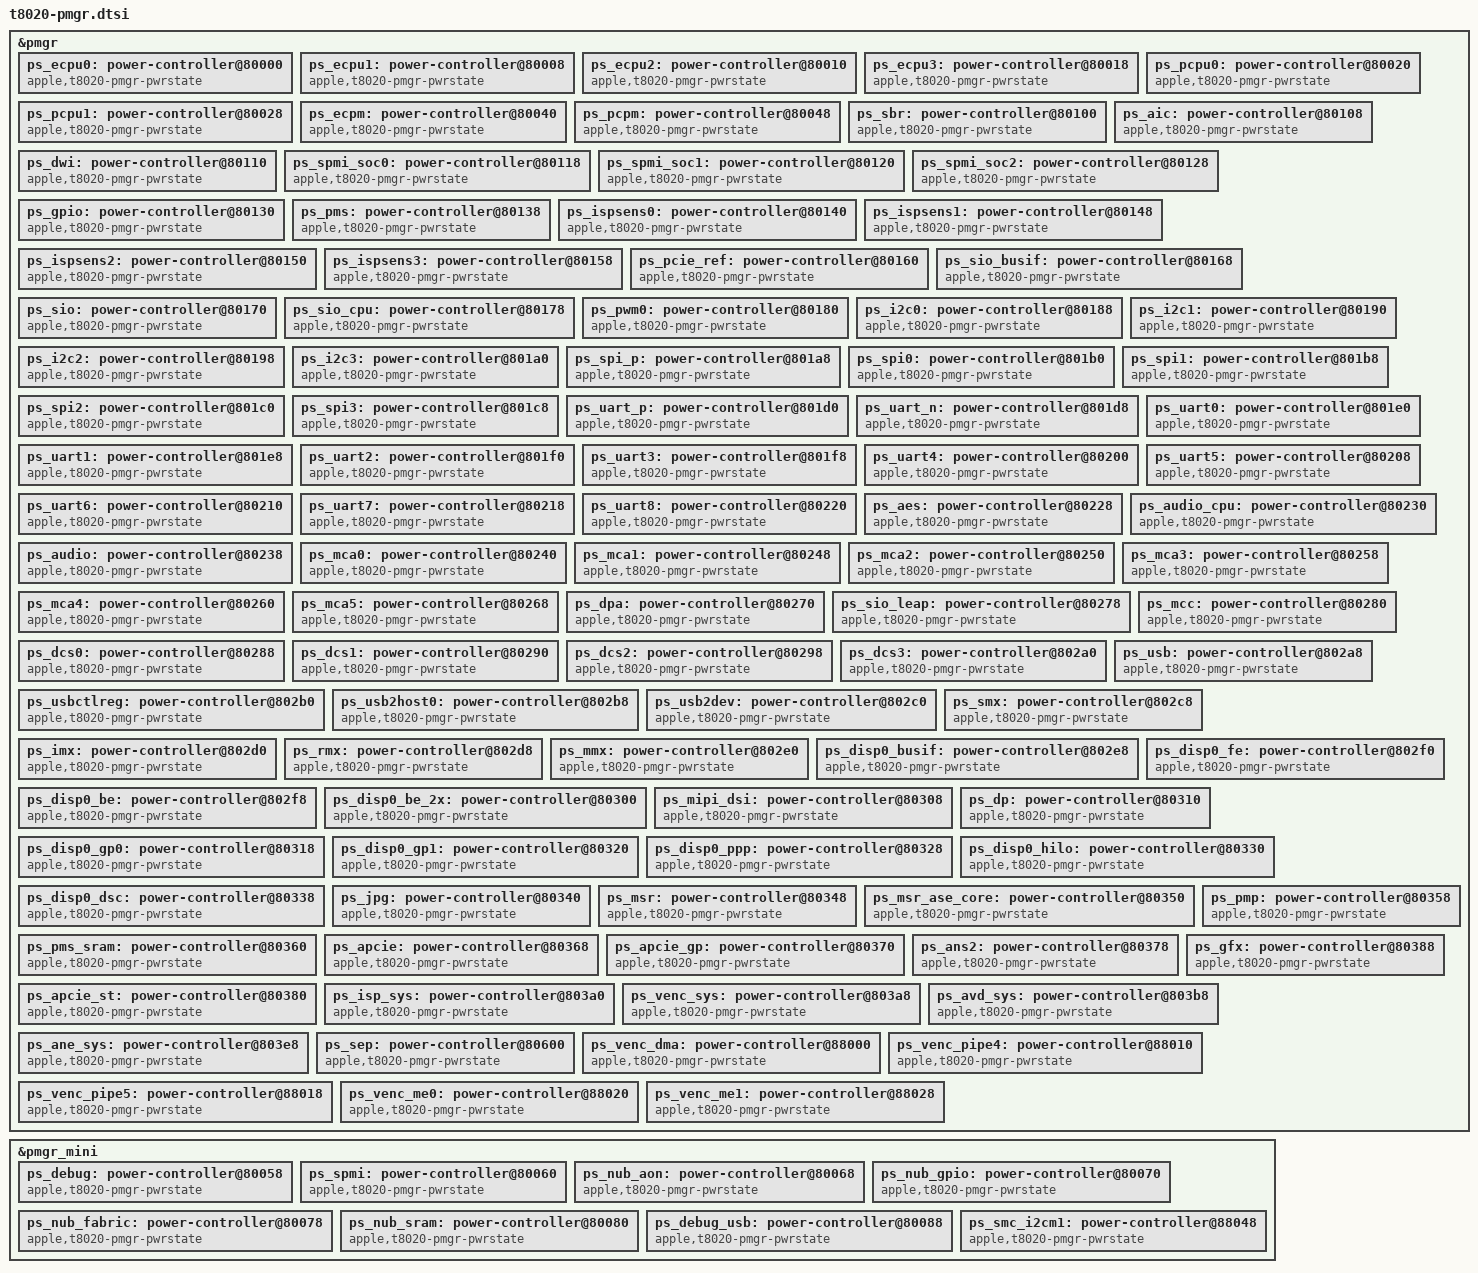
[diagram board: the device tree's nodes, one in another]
// SPDX-License-Identifier: GPL-2.0+ OR MIT
/*
 * PMGR power domains for the Apple T8020 "A12" SoC
 *
 * Generated by tools/gen-pmgr.sh from the ADT in the iPhone11,6 IPSW.
 * Do not edit by hand, regenerate instead.
 *
 * Copyright (c) 2026, kiki <kieran@lavato.net>
 */



&pmgr {

	ps_ecpu0: power-controller@80000 {
		compatible = "apple,t8020-pmgr-pwrstate", "apple,pmgr-pwrstate";
		reg = <0x80000 4>;
		#power-domain-cells = <0>;
		#reset-cells = <0>;
		label = "ecpu0";
	};

	ps_ecpu1: power-controller@80008 {
		compatible = "apple,t8020-pmgr-pwrstate", "apple,pmgr-pwrstate";
		reg = <0x80008 4>;
		#power-domain-cells = <0>;
		#reset-cells = <0>;
		label = "ecpu1";
	};

	ps_ecpu2: power-controller@80010 {
		compatible = "apple,t8020-pmgr-pwrstate", "apple,pmgr-pwrstate";
		reg = <0x80010 4>;
		#power-domain-cells = <0>;
		#reset-cells = <0>;
		label = "ecpu2";
	};

	ps_ecpu3: power-controller@80018 {
		compatible = "apple,t8020-pmgr-pwrstate", "apple,pmgr-pwrstate";
		reg = <0x80018 4>;
		#power-domain-cells = <0>;
		#reset-cells = <0>;
		label = "ecpu3";
	};

	ps_pcpu0: power-controller@80020 {
		compatible = "apple,t8020-pmgr-pwrstate", "apple,pmgr-pwrstate";
		reg = <0x80020 4>;
		#power-domain-cells = <0>;
		#reset-cells = <0>;
		label = "pcpu0";
	};

	ps_pcpu1: power-controller@80028 {
		compatible = "apple,t8020-pmgr-pwrstate", "apple,pmgr-pwrstate";
		reg = <0x80028 4>;
		#power-domain-cells = <0>;
		#reset-cells = <0>;
		label = "pcpu1";
	};

	ps_ecpm: power-controller@80040 {
		compatible = "apple,t8020-pmgr-pwrstate", "apple,pmgr-pwrstate";
		reg = <0x80040 4>;
		#power-domain-cells = <0>;
		#reset-cells = <0>;
		label = "ecpm";
	};

	ps_pcpm: power-controller@80048 {
		compatible = "apple,t8020-pmgr-pwrstate", "apple,pmgr-pwrstate";
		reg = <0x80048 4>;
		#power-domain-cells = <0>;
		#reset-cells = <0>;
		label = "pcpm";
	};

	ps_sbr: power-controller@80100 {
		compatible = "apple,t8020-pmgr-pwrstate", "apple,pmgr-pwrstate";
		reg = <0x80100 4>;
		#power-domain-cells = <0>;
		#reset-cells = <0>;
		label = "sbr";
		apple,always-on;
	};

	ps_aic: power-controller@80108 {
		compatible = "apple,t8020-pmgr-pwrstate", "apple,pmgr-pwrstate";
		reg = <0x80108 4>;
		#power-domain-cells = <0>;
		#reset-cells = <0>;
		label = "aic";
	};

	ps_dwi: power-controller@80110 {
		compatible = "apple,t8020-pmgr-pwrstate", "apple,pmgr-pwrstate";
		reg = <0x80110 4>;
		#power-domain-cells = <0>;
		#reset-cells = <0>;
		label = "dwi";
	};

	ps_spmi_soc0: power-controller@80118 {
		compatible = "apple,t8020-pmgr-pwrstate", "apple,pmgr-pwrstate";
		reg = <0x80118 4>;
		#power-domain-cells = <0>;
		#reset-cells = <0>;
		label = "spmi_soc0";
	};

	ps_spmi_soc1: power-controller@80120 {
		compatible = "apple,t8020-pmgr-pwrstate", "apple,pmgr-pwrstate";
		reg = <0x80120 4>;
		#power-domain-cells = <0>;
		#reset-cells = <0>;
		label = "spmi_soc1";
	};

	ps_spmi_soc2: power-controller@80128 {
		compatible = "apple,t8020-pmgr-pwrstate", "apple,pmgr-pwrstate";
		reg = <0x80128 4>;
		#power-domain-cells = <0>;
		#reset-cells = <0>;
		label = "spmi_soc2";
	};

	ps_gpio: power-controller@80130 {
		compatible = "apple,t8020-pmgr-pwrstate", "apple,pmgr-pwrstate";
		reg = <0x80130 4>;
		#power-domain-cells = <0>;
		#reset-cells = <0>;
		label = "gpio";
	};

	ps_pms: power-controller@80138 {
		compatible = "apple,t8020-pmgr-pwrstate", "apple,pmgr-pwrstate";
		reg = <0x80138 4>;
		#power-domain-cells = <0>;
		#reset-cells = <0>;
		label = "pms";
		apple,always-on;
	};

	ps_ispsens0: power-controller@80140 {
		compatible = "apple,t8020-pmgr-pwrstate", "apple,pmgr-pwrstate";
		reg = <0x80140 4>;
		#power-domain-cells = <0>;
		#reset-cells = <0>;
		label = "ispsens0";
	};

	ps_ispsens1: power-controller@80148 {
		compatible = "apple,t8020-pmgr-pwrstate", "apple,pmgr-pwrstate";
		reg = <0x80148 4>;
		#power-domain-cells = <0>;
		#reset-cells = <0>;
		label = "ispsens1";
	};

	ps_ispsens2: power-controller@80150 {
		compatible = "apple,t8020-pmgr-pwrstate", "apple,pmgr-pwrstate";
		reg = <0x80150 4>;
		#power-domain-cells = <0>;
		#reset-cells = <0>;
		label = "ispsens2";
	};

	ps_ispsens3: power-controller@80158 {
		compatible = "apple,t8020-pmgr-pwrstate", "apple,pmgr-pwrstate";
		reg = <0x80158 4>;
		#power-domain-cells = <0>;
		#reset-cells = <0>;
		label = "ispsens3";
	};

	ps_pcie_ref: power-controller@80160 {
		compatible = "apple,t8020-pmgr-pwrstate", "apple,pmgr-pwrstate";
		reg = <0x80160 4>;
		#power-domain-cells = <0>;
		#reset-cells = <0>;
		label = "pcie_ref";
	};

	ps_sio_busif: power-controller@80168 {
		compatible = "apple,t8020-pmgr-pwrstate", "apple,pmgr-pwrstate";
		reg = <0x80168 4>;
		#power-domain-cells = <0>;
		#reset-cells = <0>;
		label = "sio_busif";
	};

	ps_sio: power-controller@80170 {
		compatible = "apple,t8020-pmgr-pwrstate", "apple,pmgr-pwrstate";
		reg = <0x80170 4>;
		#power-domain-cells = <0>;
		#reset-cells = <0>;
		label = "sio";
		power-domains = <&ps_sio_busif>;
	};

	ps_sio_cpu: power-controller@80178 {
		compatible = "apple,t8020-pmgr-pwrstate", "apple,pmgr-pwrstate";
		reg = <0x80178 4>;
		#power-domain-cells = <0>;
		#reset-cells = <0>;
		label = "sio_cpu";
		power-domains = <&ps_sio>;
	};

	ps_pwm0: power-controller@80180 {
		compatible = "apple,t8020-pmgr-pwrstate", "apple,pmgr-pwrstate";
		reg = <0x80180 4>;
		#power-domain-cells = <0>;
		#reset-cells = <0>;
		label = "pwm0";
		power-domains = <&ps_sio>;
	};

	ps_i2c0: power-controller@80188 {
		compatible = "apple,t8020-pmgr-pwrstate", "apple,pmgr-pwrstate";
		reg = <0x80188 4>;
		#power-domain-cells = <0>;
		#reset-cells = <0>;
		label = "i2c0";
		power-domains = <&ps_sio>;
	};

	ps_i2c1: power-controller@80190 {
		compatible = "apple,t8020-pmgr-pwrstate", "apple,pmgr-pwrstate";
		reg = <0x80190 4>;
		#power-domain-cells = <0>;
		#reset-cells = <0>;
		label = "i2c1";
		power-domains = <&ps_sio>;
	};

	ps_i2c2: power-controller@80198 {
		compatible = "apple,t8020-pmgr-pwrstate", "apple,pmgr-pwrstate";
		reg = <0x80198 4>;
		#power-domain-cells = <0>;
		#reset-cells = <0>;
		label = "i2c2";
		power-domains = <&ps_sio>;
	};

	ps_i2c3: power-controller@801a0 {
		compatible = "apple,t8020-pmgr-pwrstate", "apple,pmgr-pwrstate";
		reg = <0x801a0 4>;
		#power-domain-cells = <0>;
		#reset-cells = <0>;
		label = "i2c3";
		power-domains = <&ps_sio>;
	};

	ps_spi_p: power-controller@801a8 {
		compatible = "apple,t8020-pmgr-pwrstate", "apple,pmgr-pwrstate";
		reg = <0x801a8 4>;
		#power-domain-cells = <0>;
		#reset-cells = <0>;
		label = "spi_p";
		power-domains = <&ps_sio_busif>, <&ps_sio>;
	};

	ps_spi0: power-controller@801b0 {
		compatible = "apple,t8020-pmgr-pwrstate", "apple,pmgr-pwrstate";
		reg = <0x801b0 4>;
		#power-domain-cells = <0>;
		#reset-cells = <0>;
		label = "spi0";
		power-domains = <&ps_spi_p>;
	};

	ps_spi1: power-controller@801b8 {
		compatible = "apple,t8020-pmgr-pwrstate", "apple,pmgr-pwrstate";
		reg = <0x801b8 4>;
		#power-domain-cells = <0>;
		#reset-cells = <0>;
		label = "spi1";
		power-domains = <&ps_spi_p>;
	};

	ps_spi2: power-controller@801c0 {
		compatible = "apple,t8020-pmgr-pwrstate", "apple,pmgr-pwrstate";
		reg = <0x801c0 4>;
		#power-domain-cells = <0>;
		#reset-cells = <0>;
		label = "spi2";
		power-domains = <&ps_spi_p>;
	};

	ps_spi3: power-controller@801c8 {
		compatible = "apple,t8020-pmgr-pwrstate", "apple,pmgr-pwrstate";
		reg = <0x801c8 4>;
		#power-domain-cells = <0>;
		#reset-cells = <0>;
		label = "spi3";
		power-domains = <&ps_spi_p>;
	};

	ps_uart_p: power-controller@801d0 {
		compatible = "apple,t8020-pmgr-pwrstate", "apple,pmgr-pwrstate";
		reg = <0x801d0 4>;
		#power-domain-cells = <0>;
		#reset-cells = <0>;
		label = "uart_p";
		power-domains = <&ps_sio>;
	};

	ps_uart_n: power-controller@801d8 {
		compatible = "apple,t8020-pmgr-pwrstate", "apple,pmgr-pwrstate";
		reg = <0x801d8 4>;
		#power-domain-cells = <0>;
		#reset-cells = <0>;
		label = "uart_n";
		power-domains = <&ps_uart_p>;
	};

	ps_uart0: power-controller@801e0 {
		compatible = "apple,t8020-pmgr-pwrstate", "apple,pmgr-pwrstate";
		reg = <0x801e0 4>;
		#power-domain-cells = <0>;
		#reset-cells = <0>;
		label = "uart0";
		power-domains = <&ps_uart_p>;
	};

	ps_uart1: power-controller@801e8 {
		compatible = "apple,t8020-pmgr-pwrstate", "apple,pmgr-pwrstate";
		reg = <0x801e8 4>;
		#power-domain-cells = <0>;
		#reset-cells = <0>;
		label = "uart1";
		power-domains = <&ps_uart_p>;
	};

	ps_uart2: power-controller@801f0 {
		compatible = "apple,t8020-pmgr-pwrstate", "apple,pmgr-pwrstate";
		reg = <0x801f0 4>;
		#power-domain-cells = <0>;
		#reset-cells = <0>;
		label = "uart2";
		power-domains = <&ps_uart_p>;
	};

	ps_uart3: power-controller@801f8 {
		compatible = "apple,t8020-pmgr-pwrstate", "apple,pmgr-pwrstate";
		reg = <0x801f8 4>;
		#power-domain-cells = <0>;
		#reset-cells = <0>;
		label = "uart3";
		power-domains = <&ps_uart_p>;
	};

	ps_uart4: power-controller@80200 {
		compatible = "apple,t8020-pmgr-pwrstate", "apple,pmgr-pwrstate";
		reg = <0x80200 4>;
		#power-domain-cells = <0>;
		#reset-cells = <0>;
		label = "uart4";
		power-domains = <&ps_uart_p>;
	};

	ps_uart5: power-controller@80208 {
		compatible = "apple,t8020-pmgr-pwrstate", "apple,pmgr-pwrstate";
		reg = <0x80208 4>;
		#power-domain-cells = <0>;
		#reset-cells = <0>;
		label = "uart5";
		power-domains = <&ps_uart_p>;
	};

	ps_uart6: power-controller@80210 {
		compatible = "apple,t8020-pmgr-pwrstate", "apple,pmgr-pwrstate";
		reg = <0x80210 4>;
		#power-domain-cells = <0>;
		#reset-cells = <0>;
		label = "uart6";
		power-domains = <&ps_uart_p>;
	};

	ps_uart7: power-controller@80218 {
		compatible = "apple,t8020-pmgr-pwrstate", "apple,pmgr-pwrstate";
		reg = <0x80218 4>;
		#power-domain-cells = <0>;
		#reset-cells = <0>;
		label = "uart7";
		power-domains = <&ps_uart_p>;
	};

	ps_uart8: power-controller@80220 {
		compatible = "apple,t8020-pmgr-pwrstate", "apple,pmgr-pwrstate";
		reg = <0x80220 4>;
		#power-domain-cells = <0>;
		#reset-cells = <0>;
		label = "uart8";
		power-domains = <&ps_uart_p>;
	};

	ps_aes: power-controller@80228 {
		compatible = "apple,t8020-pmgr-pwrstate", "apple,pmgr-pwrstate";
		reg = <0x80228 4>;
		#power-domain-cells = <0>;
		#reset-cells = <0>;
		label = "aes";
		power-domains = <&ps_sio>;
	};

	ps_audio_cpu: power-controller@80230 {
		compatible = "apple,t8020-pmgr-pwrstate", "apple,pmgr-pwrstate";
		reg = <0x80230 4>;
		#power-domain-cells = <0>;
		#reset-cells = <0>;
		label = "audio_cpu";
		power-domains = <&ps_sio>;
	};

	ps_audio: power-controller@80238 {
		compatible = "apple,t8020-pmgr-pwrstate", "apple,pmgr-pwrstate";
		reg = <0x80238 4>;
		#power-domain-cells = <0>;
		#reset-cells = <0>;
		label = "audio";
		power-domains = <&ps_sio>;
	};

	ps_mca0: power-controller@80240 {
		compatible = "apple,t8020-pmgr-pwrstate", "apple,pmgr-pwrstate";
		reg = <0x80240 4>;
		#power-domain-cells = <0>;
		#reset-cells = <0>;
		label = "mca0";
		power-domains = <&ps_audio>;
	};

	ps_mca1: power-controller@80248 {
		compatible = "apple,t8020-pmgr-pwrstate", "apple,pmgr-pwrstate";
		reg = <0x80248 4>;
		#power-domain-cells = <0>;
		#reset-cells = <0>;
		label = "mca1";
		power-domains = <&ps_audio>;
	};

	ps_mca2: power-controller@80250 {
		compatible = "apple,t8020-pmgr-pwrstate", "apple,pmgr-pwrstate";
		reg = <0x80250 4>;
		#power-domain-cells = <0>;
		#reset-cells = <0>;
		label = "mca2";
		power-domains = <&ps_audio>;
	};

	ps_mca3: power-controller@80258 {
		compatible = "apple,t8020-pmgr-pwrstate", "apple,pmgr-pwrstate";
		reg = <0x80258 4>;
		#power-domain-cells = <0>;
		#reset-cells = <0>;
		label = "mca3";
		power-domains = <&ps_audio>;
	};

	ps_mca4: power-controller@80260 {
		compatible = "apple,t8020-pmgr-pwrstate", "apple,pmgr-pwrstate";
		reg = <0x80260 4>;
		#power-domain-cells = <0>;
		#reset-cells = <0>;
		label = "mca4";
		power-domains = <&ps_audio>;
	};

	ps_mca5: power-controller@80268 {
		compatible = "apple,t8020-pmgr-pwrstate", "apple,pmgr-pwrstate";
		reg = <0x80268 4>;
		#power-domain-cells = <0>;
		#reset-cells = <0>;
		label = "mca5";
		power-domains = <&ps_audio>;
	};

	ps_dpa: power-controller@80270 {
		compatible = "apple,t8020-pmgr-pwrstate", "apple,pmgr-pwrstate";
		reg = <0x80270 4>;
		#power-domain-cells = <0>;
		#reset-cells = <0>;
		label = "dpa";
		power-domains = <&ps_audio>;
	};

	ps_sio_leap: power-controller@80278 {
		compatible = "apple,t8020-pmgr-pwrstate", "apple,pmgr-pwrstate";
		reg = <0x80278 4>;
		#power-domain-cells = <0>;
		#reset-cells = <0>;
		label = "sio_leap";
		power-domains = <&ps_audio>;
	};

	ps_mcc: power-controller@80280 {
		compatible = "apple,t8020-pmgr-pwrstate", "apple,pmgr-pwrstate";
		reg = <0x80280 4>;
		#power-domain-cells = <0>;
		#reset-cells = <0>;
		label = "mcc";
		apple,always-on;
	};

	ps_dcs0: power-controller@80288 {
		compatible = "apple,t8020-pmgr-pwrstate", "apple,pmgr-pwrstate";
		reg = <0x80288 4>;
		#power-domain-cells = <0>;
		#reset-cells = <0>;
		label = "dcs0";
		apple,always-on;
	};

	ps_dcs1: power-controller@80290 {
		compatible = "apple,t8020-pmgr-pwrstate", "apple,pmgr-pwrstate";
		reg = <0x80290 4>;
		#power-domain-cells = <0>;
		#reset-cells = <0>;
		label = "dcs1";
		apple,always-on;
	};

	ps_dcs2: power-controller@80298 {
		compatible = "apple,t8020-pmgr-pwrstate", "apple,pmgr-pwrstate";
		reg = <0x80298 4>;
		#power-domain-cells = <0>;
		#reset-cells = <0>;
		label = "dcs2";
		apple,always-on;
	};

	ps_dcs3: power-controller@802a0 {
		compatible = "apple,t8020-pmgr-pwrstate", "apple,pmgr-pwrstate";
		reg = <0x802a0 4>;
		#power-domain-cells = <0>;
		#reset-cells = <0>;
		label = "dcs3";
		apple,always-on;
	};

	ps_usb: power-controller@802a8 {
		compatible = "apple,t8020-pmgr-pwrstate", "apple,pmgr-pwrstate";
		reg = <0x802a8 4>;
		#power-domain-cells = <0>;
		#reset-cells = <0>;
		label = "usb";
	};

	ps_usbctlreg: power-controller@802b0 {
		compatible = "apple,t8020-pmgr-pwrstate", "apple,pmgr-pwrstate";
		reg = <0x802b0 4>;
		#power-domain-cells = <0>;
		#reset-cells = <0>;
		label = "usbctlreg";
		power-domains = <&ps_usb>;
	};

	ps_usb2host0: power-controller@802b8 {
		compatible = "apple,t8020-pmgr-pwrstate", "apple,pmgr-pwrstate";
		reg = <0x802b8 4>;
		#power-domain-cells = <0>;
		#reset-cells = <0>;
		label = "usb2host0";
		power-domains = <&ps_usbctlreg>;
	};

	ps_usb2dev: power-controller@802c0 {
		compatible = "apple,t8020-pmgr-pwrstate", "apple,pmgr-pwrstate";
		reg = <0x802c0 4>;
		#power-domain-cells = <0>;
		#reset-cells = <0>;
		label = "usb2dev";
		power-domains = <&ps_usb>;
	};

	ps_smx: power-controller@802c8 {
		compatible = "apple,t8020-pmgr-pwrstate", "apple,pmgr-pwrstate";
		reg = <0x802c8 4>;
		#power-domain-cells = <0>;
		#reset-cells = <0>;
		label = "smx";
		apple,always-on;
	};

	ps_imx: power-controller@802d0 {
		compatible = "apple,t8020-pmgr-pwrstate", "apple,pmgr-pwrstate";
		reg = <0x802d0 4>;
		#power-domain-cells = <0>;
		#reset-cells = <0>;
		label = "imx";
		apple,always-on;
	};

	ps_rmx: power-controller@802d8 {
		compatible = "apple,t8020-pmgr-pwrstate", "apple,pmgr-pwrstate";
		reg = <0x802d8 4>;
		#power-domain-cells = <0>;
		#reset-cells = <0>;
		label = "rmx";
	};

	ps_mmx: power-controller@802e0 {
		compatible = "apple,t8020-pmgr-pwrstate", "apple,pmgr-pwrstate";
		reg = <0x802e0 4>;
		#power-domain-cells = <0>;
		#reset-cells = <0>;
		label = "mmx";
	};

	ps_disp0_busif: power-controller@802e8 {
		compatible = "apple,t8020-pmgr-pwrstate", "apple,pmgr-pwrstate";
		reg = <0x802e8 4>;
		#power-domain-cells = <0>;
		#reset-cells = <0>;
		label = "disp0_busif";
		power-domains = <&ps_rmx>;
	};

	ps_disp0_fe: power-controller@802f0 {
		compatible = "apple,t8020-pmgr-pwrstate", "apple,pmgr-pwrstate";
		reg = <0x802f0 4>;
		#power-domain-cells = <0>;
		#reset-cells = <0>;
		label = "disp0_fe";
		power-domains = <&ps_disp0_busif>;
	};

	ps_disp0_be: power-controller@802f8 {
		compatible = "apple,t8020-pmgr-pwrstate", "apple,pmgr-pwrstate";
		reg = <0x802f8 4>;
		#power-domain-cells = <0>;
		#reset-cells = <0>;
		label = "disp0_be";
		power-domains = <&ps_disp0_fe>;
	};

	ps_disp0_be_2x: power-controller@80300 {
		compatible = "apple,t8020-pmgr-pwrstate", "apple,pmgr-pwrstate";
		reg = <0x80300 4>;
		#power-domain-cells = <0>;
		#reset-cells = <0>;
		label = "disp0_be_2x";
	};

	ps_mipi_dsi: power-controller@80308 {
		compatible = "apple,t8020-pmgr-pwrstate", "apple,pmgr-pwrstate";
		reg = <0x80308 4>;
		#power-domain-cells = <0>;
		#reset-cells = <0>;
		label = "mipi_dsi";
		power-domains = <&ps_disp0_be>;
	};

	ps_dp: power-controller@80310 {
		compatible = "apple,t8020-pmgr-pwrstate", "apple,pmgr-pwrstate";
		reg = <0x80310 4>;
		#power-domain-cells = <0>;
		#reset-cells = <0>;
		label = "dp";
		power-domains = <&ps_disp0_be>;
	};

	ps_disp0_gp0: power-controller@80318 {
		compatible = "apple,t8020-pmgr-pwrstate", "apple,pmgr-pwrstate";
		reg = <0x80318 4>;
		#power-domain-cells = <0>;
		#reset-cells = <0>;
		label = "disp0_gp0";
		power-domains = <&ps_disp0_be>;
	};

	ps_disp0_gp1: power-controller@80320 {
		compatible = "apple,t8020-pmgr-pwrstate", "apple,pmgr-pwrstate";
		reg = <0x80320 4>;
		#power-domain-cells = <0>;
		#reset-cells = <0>;
		label = "disp0_gp1";
		power-domains = <&ps_disp0_gp0>;
	};

	ps_disp0_ppp: power-controller@80328 {
		compatible = "apple,t8020-pmgr-pwrstate", "apple,pmgr-pwrstate";
		reg = <0x80328 4>;
		#power-domain-cells = <0>;
		#reset-cells = <0>;
		label = "disp0_ppp";
		power-domains = <&ps_disp0_gp1>;
	};

	ps_disp0_hilo: power-controller@80330 {
		compatible = "apple,t8020-pmgr-pwrstate", "apple,pmgr-pwrstate";
		reg = <0x80330 4>;
		#power-domain-cells = <0>;
		#reset-cells = <0>;
		label = "disp0_hilo";
		power-domains = <&ps_disp0_ppp>;
	};

	ps_disp0_dsc: power-controller@80338 {
		compatible = "apple,t8020-pmgr-pwrstate", "apple,pmgr-pwrstate";
		reg = <0x80338 4>;
		#power-domain-cells = <0>;
		#reset-cells = <0>;
		label = "disp0_dsc";
		power-domains = <&ps_disp0_be>;
	};

	ps_jpg: power-controller@80340 {
		compatible = "apple,t8020-pmgr-pwrstate", "apple,pmgr-pwrstate";
		reg = <0x80340 4>;
		#power-domain-cells = <0>;
		#reset-cells = <0>;
		label = "jpg";
		power-domains = <&ps_mmx>;
	};

	ps_msr: power-controller@80348 {
		compatible = "apple,t8020-pmgr-pwrstate", "apple,pmgr-pwrstate";
		reg = <0x80348 4>;
		#power-domain-cells = <0>;
		#reset-cells = <0>;
		label = "msr";
		power-domains = <&ps_mmx>;
	};

	ps_msr_ase_core: power-controller@80350 {
		compatible = "apple,t8020-pmgr-pwrstate", "apple,pmgr-pwrstate";
		reg = <0x80350 4>;
		#power-domain-cells = <0>;
		#reset-cells = <0>;
		label = "msr_ase_core";
		power-domains = <&ps_msr>;
	};

	ps_pmp: power-controller@80358 {
		compatible = "apple,t8020-pmgr-pwrstate", "apple,pmgr-pwrstate";
		reg = <0x80358 4>;
		#power-domain-cells = <0>;
		#reset-cells = <0>;
		label = "pmp";
		apple,always-on;
	};

	ps_pms_sram: power-controller@80360 {
		compatible = "apple,t8020-pmgr-pwrstate", "apple,pmgr-pwrstate";
		reg = <0x80360 4>;
		#power-domain-cells = <0>;
		#reset-cells = <0>;
		label = "pms_sram";
		apple,always-on;
	};

	ps_apcie: power-controller@80368 {
		compatible = "apple,t8020-pmgr-pwrstate", "apple,pmgr-pwrstate";
		reg = <0x80368 4>;
		#power-domain-cells = <0>;
		#reset-cells = <0>;
		label = "apcie";
		power-domains = <&ps_imx>;
	};

	ps_apcie_gp: power-controller@80370 {
		compatible = "apple,t8020-pmgr-pwrstate", "apple,pmgr-pwrstate";
		reg = <0x80370 4>;
		#power-domain-cells = <0>;
		#reset-cells = <0>;
		label = "apcie_gp";
		power-domains = <&ps_apcie>;
	};

	ps_ans2: power-controller@80378 {
		compatible = "apple,t8020-pmgr-pwrstate", "apple,pmgr-pwrstate";
		reg = <0x80378 4>;
		#power-domain-cells = <0>;
		#reset-cells = <0>;
		label = "ans2";
	};

	ps_apcie_st: power-controller@80380 {
		compatible = "apple,t8020-pmgr-pwrstate", "apple,pmgr-pwrstate";
		reg = <0x80380 4>;
		#power-domain-cells = <0>;
		#reset-cells = <0>;
		label = "apcie_st";
		power-domains = <&ps_apcie>, <&ps_ans2>;
	};

	ps_gfx: power-controller@80388 {
		compatible = "apple,t8020-pmgr-pwrstate", "apple,pmgr-pwrstate";
		reg = <0x80388 4>;
		#power-domain-cells = <0>;
		#reset-cells = <0>;
		label = "gfx";
	};

	ps_isp_sys: power-controller@803a0 {
		compatible = "apple,t8020-pmgr-pwrstate", "apple,pmgr-pwrstate";
		reg = <0x803a0 4>;
		#power-domain-cells = <0>;
		#reset-cells = <0>;
		label = "isp_sys";
		power-domains = <&ps_rmx>;
	};

	ps_venc_sys: power-controller@803a8 {
		compatible = "apple,t8020-pmgr-pwrstate", "apple,pmgr-pwrstate";
		reg = <0x803a8 4>;
		#power-domain-cells = <0>;
		#reset-cells = <0>;
		label = "venc_sys";
		power-domains = <&ps_mmx>;
	};

	ps_avd_sys: power-controller@803b8 {
		compatible = "apple,t8020-pmgr-pwrstate", "apple,pmgr-pwrstate";
		reg = <0x803b8 4>;
		#power-domain-cells = <0>;
		#reset-cells = <0>;
		label = "avd_sys";
		power-domains = <&ps_mmx>;
	};

	ps_ane_sys: power-controller@803e8 {
		compatible = "apple,t8020-pmgr-pwrstate", "apple,pmgr-pwrstate";
		reg = <0x803e8 4>;
		#power-domain-cells = <0>;
		#reset-cells = <0>;
		label = "ane_sys";
		power-domains = <&ps_mmx>;
	};

	ps_sep: power-controller@80600 {
		compatible = "apple,t8020-pmgr-pwrstate", "apple,pmgr-pwrstate";
		reg = <0x80600 4>;
		#power-domain-cells = <0>;
		#reset-cells = <0>;
		label = "sep";
		apple,always-on;
	};

	ps_venc_dma: power-controller@88000 {
		compatible = "apple,t8020-pmgr-pwrstate", "apple,pmgr-pwrstate";
		reg = <0x88000 4>;
		#power-domain-cells = <0>;
		#reset-cells = <0>;
		label = "venc_dma";
		power-domains = <&ps_venc_sys>;
	};

	ps_venc_pipe4: power-controller@88010 {
		compatible = "apple,t8020-pmgr-pwrstate", "apple,pmgr-pwrstate";
		reg = <0x88010 4>;
		#power-domain-cells = <0>;
		#reset-cells = <0>;
		label = "venc_pipe4";
		power-domains = <&ps_venc_dma>;
	};

	ps_venc_pipe5: power-controller@88018 {
		compatible = "apple,t8020-pmgr-pwrstate", "apple,pmgr-pwrstate";
		reg = <0x88018 4>;
		#power-domain-cells = <0>;
		#reset-cells = <0>;
		label = "venc_pipe5";
		power-domains = <&ps_venc_dma>;
	};

	ps_venc_me0: power-controller@88020 {
		compatible = "apple,t8020-pmgr-pwrstate", "apple,pmgr-pwrstate";
		reg = <0x88020 4>;
		#power-domain-cells = <0>;
		#reset-cells = <0>;
		label = "venc_me0";
	};

	ps_venc_me1: power-controller@88028 {
		compatible = "apple,t8020-pmgr-pwrstate", "apple,pmgr-pwrstate";
		reg = <0x88028 4>;
		#power-domain-cells = <0>;
		#reset-cells = <0>;
		label = "venc_me1";
	};
};

&pmgr_mini {

	ps_debug: power-controller@80058 {
		compatible = "apple,t8020-pmgr-pwrstate", "apple,pmgr-pwrstate";
		reg = <0x80058 4>;
		#power-domain-cells = <0>;
		#reset-cells = <0>;
		label = "debug";
		apple,always-on;
	};

	ps_spmi: power-controller@80060 {
		compatible = "apple,t8020-pmgr-pwrstate", "apple,pmgr-pwrstate";
		reg = <0x80060 4>;
		#power-domain-cells = <0>;
		#reset-cells = <0>;
		label = "spmi";
		apple,always-on;
	};

	ps_nub_aon: power-controller@80068 {
		compatible = "apple,t8020-pmgr-pwrstate", "apple,pmgr-pwrstate";
		reg = <0x80068 4>;
		#power-domain-cells = <0>;
		#reset-cells = <0>;
		label = "nub_aon";
		apple,always-on;
	};

	ps_nub_gpio: power-controller@80070 {
		compatible = "apple,t8020-pmgr-pwrstate", "apple,pmgr-pwrstate";
		reg = <0x80070 4>;
		#power-domain-cells = <0>;
		#reset-cells = <0>;
		label = "nub_gpio";
		apple,always-on;
	};

	ps_nub_fabric: power-controller@80078 {
		compatible = "apple,t8020-pmgr-pwrstate", "apple,pmgr-pwrstate";
		reg = <0x80078 4>;
		#power-domain-cells = <0>;
		#reset-cells = <0>;
		label = "nub_fabric";
		apple,always-on;
	};

	ps_nub_sram: power-controller@80080 {
		compatible = "apple,t8020-pmgr-pwrstate", "apple,pmgr-pwrstate";
		reg = <0x80080 4>;
		#power-domain-cells = <0>;
		#reset-cells = <0>;
		label = "nub_sram";
		apple,always-on;
	};

	ps_debug_usb: power-controller@80088 {
		compatible = "apple,t8020-pmgr-pwrstate", "apple,pmgr-pwrstate";
		reg = <0x80088 4>;
		#power-domain-cells = <0>;
		#reset-cells = <0>;
		label = "debug_usb";
		apple,always-on;
		power-domains = <&ps_debug>;
	};

	ps_smc_i2cm1: power-controller@88048 {
		compatible = "apple,t8020-pmgr-pwrstate", "apple,pmgr-pwrstate";
		reg = <0x88048 4>;
		#power-domain-cells = <0>;
		#reset-cells = <0>;
		label = "smc-i2cm1";
	};
};
